# RX64M_USB_Pilot register map
File version: 1.0
RX64M_USB_Pilot peripheral registers generated from iodefine.h (pilot).
Registers are 32-bit, read-write, reset 0x0 unless marked. A register's access mark holds for its fields unless they carry their own. Offsets are from the block's base; lines under a group give offsets from that group; [hi:lo] are bit positions; {n}, {i} and the like mark numbered series; 'fields as' and 'values as' point back to an identical list; <NAME> marks a mode.

## Memory map
0x000A0400 USB size 0x8

## USB
Base 0x000A0400
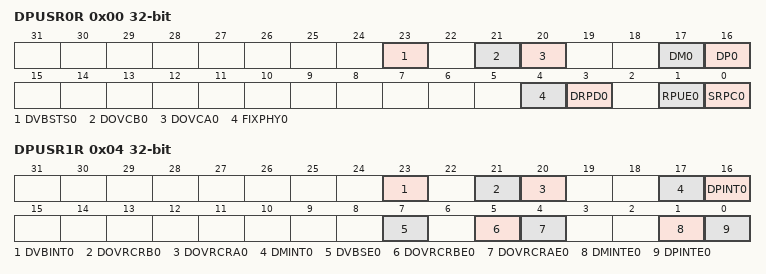
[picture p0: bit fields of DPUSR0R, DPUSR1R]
0x00 DPUSR0R (reset mask 0xFF4CFFFF)
  [23] DVBSTS0, [21] DOVCB0, [20] DOVCA0, [17] DM0, [16] DP0, [4] FIXPHY0, [3] DRPD0, [1] RPUE0, [0] SRPC0
0x04 DPUSR1R
  [23] DVBINT0, [21] DOVRCRB0, [20] DOVRCRA0, [17] DMINT0, [16] DPINT0, [7] DVBSE0, [5] DOVRCRBE0, [4] DOVRCRAE0, [1] DMINTE0, [0] DPINTE0
